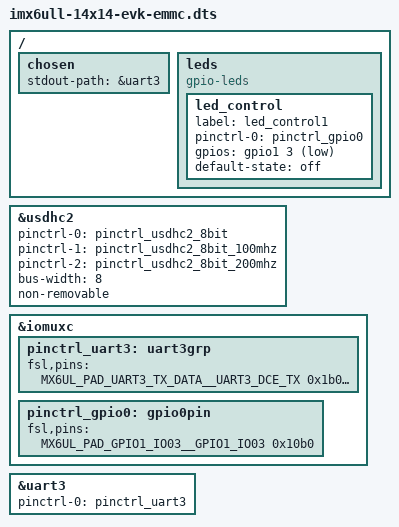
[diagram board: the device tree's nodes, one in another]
/*
 * Copyright 2019 NXP
 *
 * This program is free software; you can redistribute it and/or
 * modify it under the terms of the GNU General Public License
 * as published by the Free Software Foundation; either version 2
 * of the License, or (at your option) any later version.
 */

#include "imx6ull-14x14-evk.dts"
/{
	chosen {
		stdout-path = &uart3;
	};

	leds: leds {
		compatible = "gpio-leds";
		status = "okay";
	};
};
&usdhc2 {
	pinctrl-names = "default", "state_100mhz", "state_200mhz";
	pinctrl-0 = <&pinctrl_usdhc2_8bit>;
	pinctrl-1 = <&pinctrl_usdhc2_8bit_100mhz>;
	pinctrl-2 = <&pinctrl_usdhc2_8bit_200mhz>;
	bus-width = <8>;
	non-removable;
	status = "okay";
};

&iomuxc {
	pinctrl_uart3: uart3grp {
		fsl,pins = <
			MX6UL_PAD_UART3_TX_DATA__UART3_DCE_TX 0x1b0b1
			MX6UL_PAD_UART3_RX_DATA__UART3_DCE_RX 0x1b0b1
		>;
		bootph-all;
	};
	pinctrl_gpio0: gpio0pin {
		fsl,pins = <
			MX6UL_PAD_GPIO1_IO03__GPIO1_IO03 0x10b0
		>;
	};
};
&uart3 {
	pinctrl-names = "default";
	pinctrl-0 = <&pinctrl_uart3>;
	bootph-all;
	status = "okay";
};

&leds {
	led_control {
		label = "led_control1";
		pinctrl-names = "default";
		pinctrl-0 = <&pinctrl_gpio0>;
		gpios = <&gpio1 3 GPIO_ACTIVE_LOW>;
		default-state = "off";
		status = "okay";
	};

};

